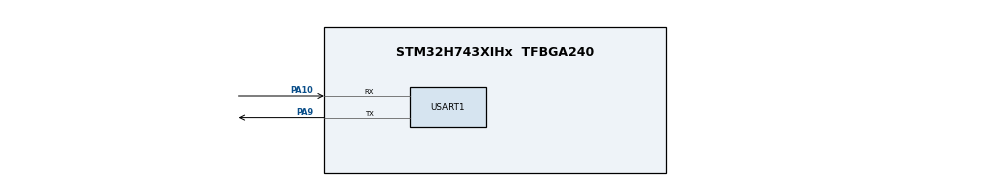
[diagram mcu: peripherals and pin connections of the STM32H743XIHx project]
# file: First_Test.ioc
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Dma.Request0=USART1_RX
Dma.Request1=USART1_TX
Dma.USART1_RX.0.Direction=DMA_PERIPH_TO_MEMORY
Dma.USART1_RX.0.EventEnable=DISABLE
Dma.USART1_RX.0.FIFOMode=DMA_FIFOMODE_DISABLE
Dma.USART1_RX.0.Instance=DMA1_Stream0
Dma.USART1_RX.0.MemDataAlignment=DMA_MDATAALIGN_BYTE
Dma.USART1_RX.0.MemInc=DMA_MINC_ENABLE
Dma.USART1_RX.0.Mode=DMA_NORMAL
Dma.USART1_RX.0.PeriphDataAlignment=DMA_PDATAALIGN_BYTE
Dma.USART1_RX.0.PeriphInc=DMA_PINC_DISABLE
Dma.USART1_RX.0.Polarity=HAL_DMAMUX_REQ_GEN_RISING
Dma.USART1_RX.0.Priority=DMA_PRIORITY_LOW
Dma.USART1_RX.0.RequestNumber=1
Dma.USART1_RX.0.SignalID=NONE
Dma.USART1_RX.0.SyncEnable=DISABLE
Dma.USART1_RX.0.SyncPolarity=HAL_DMAMUX_SYNC_NO_EVENT
Dma.USART1_RX.0.SyncRequestNumber=1
Dma.USART1_RX.0.SyncSignalID=NONE
Dma.USART1_TX.1.Direction=DMA_MEMORY_TO_PERIPH
Dma.USART1_TX.1.EventEnable=DISABLE
Dma.USART1_TX.1.FIFOMode=DMA_FIFOMODE_DISABLE
Dma.USART1_TX.1.Instance=DMA1_Stream1
Dma.USART1_TX.1.MemDataAlignment=DMA_MDATAALIGN_BYTE
Dma.USART1_TX.1.MemInc=DMA_MINC_ENABLE
Dma.USART1_TX.1.Mode=DMA_NORMAL
Dma.USART1_TX.1.PeriphDataAlignment=DMA_PDATAALIGN_BYTE
Dma.USART1_TX.1.PeriphInc=DMA_PINC_DISABLE
Dma.USART1_TX.1.Polarity=HAL_DMAMUX_REQ_GEN_RISING
Dma.USART1_TX.1.Priority=DMA_PRIORITY_LOW
Dma.USART1_TX.1.RequestNumber=1
Dma.USART1_TX.1.SignalID=NONE
Dma.USART1_TX.1.SyncEnable=DISABLE
Dma.USART1_TX.1.SyncPolarity=HAL_DMAMUX_SYNC_NO_EVENT
Dma.USART1_TX.1.SyncRequestNumber=1
Dma.USART1_TX.1.SyncSignalID=NONE
Mcu.Family=STM32H7
Mcu.Name=STM32H743XIHx
Mcu.Package=TFBGA240
NVIC.DMA1_Stream0_IRQn=true\:0\:0\:false\:false\:true\:false\:true\:true
NVIC.DMA1_Stream1_IRQn=true\:0\:0\:false\:false\:true\:false\:true\:true
NVIC.PriorityGroup=NVIC_PRIORITYGROUP_4
NVIC.USART1_IRQn=true\:1\:0\:true\:false\:true\:true\:true\:true
PA10.Mode=Asynchronous
PA10.Signal=USART1_RX
PA9.Mode=Asynchronous
PA9.Signal=USART1_TX
PH0-OSC_IN\ (PH0).Mode=HSE-External-Oscillator
PH0-OSC_IN\ (PH0).Signal=RCC_OSC_IN
PH1-OSC_OUT\ (PH1).Mode=HSE-External-Oscillator
PH1-OSC_OUT\ (PH1).Signal=RCC_OSC_OUT
ProjectManager.HeapSize=0x200
ProjectManager.StackSize=0x400
ProjectManager.TargetToolchain=MDK-ARM V5.32
RCC.ADCFreq_Value=50390625
RCC.APB1Freq_Value=100000000
RCC.APB2Freq_Value=100000000
RCC.APB3Freq_Value=100000000
RCC.APB4Freq_Value=100000000
RCC.CortexFreq_Value=400000000
RCC.D1PPRE=RCC_APB3_DIV2
RCC.D2PPRE1=RCC_APB1_DIV2
RCC.D2PPRE2=RCC_APB2_DIV2
RCC.D3PPRE=RCC_APB4_DIV2
RCC.DIVM1=5
RCC.DIVN1=160
RCC.HCLKFreq_Value=200000000
RCC.HPRE=RCC_HCLK_DIV2
RCC.PLL2FRACN=0
RCC.PLL3FRACN=0
RCC.PLLFRACN=0
RCC.PLLSourceVirtual=RCC_PLLSOURCE_HSE
RCC.SYSCLKFreq_VALUE=400000000
RCC.SYSCLKSource=RCC_SYSCLKSOURCE_PLLCLK
RCC.USBFreq_Value=400000000
USART1.VirtualMode-Asynchronous=VM_ASYNC
board=custom

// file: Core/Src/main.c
/* USER CODE BEGIN Header */
/**
  ******************************************************************************
  * @file           : main.c
  * @brief          : Main program body
  ******************************************************************************
  * @attention
  *
  * Copyright (c) 2023 STMicroelectronics.
  * All rights reserved.
  *
  * This software is licensed under terms that can be found in the LICENSE file
  * in the root directory of this software component.
  * If no LICENSE file comes with this software, it is provided AS-IS.
  * 串口收发-DMA+串口空闲中断
  ******************************************************************************
  */
/* USER CODE END Header */
#include "main.h"
#include "dma.h"
#include "usart.h"
#include "gpio.h"

/* USER CODE BEGIN PV */
uint8_t date[BUFLEN];
/* USER CODE END PV */

void SystemClock_Config(void);

/* USER CODE BEGIN 0 */

void HAL_UART_RxCpltCallback(UART_HandleTypeDef *huart)  //接收中断回调函数
{
    HAL_UART_Transmit_DMA(&huart1,date,BUFLEN);
    HAL_UART_Receive_IT(&huart1,date,BUFLEN);
}
/* USER CODE END 0 */

int main(void)
{

  /* MCU Configuration--------------------------------------------------------*/

  /* Reset of all peripherals, Initializes the Flash interface and the Systick. */
  HAL_Init();

  /* Configure the system clock */
  SystemClock_Config();

  /* Initialize all configured peripherals */
  MX_GPIO_Init();
  MX_DMA_Init();
  MX_USART1_UART_Init();
  /* USER CODE BEGIN 2 */
    HAL_UART_Receive_DMA(&huart1,date,20);
    __HAL_UART_CLEAR_IDLEFLAG(&huart1);  				//清空中断标志
    __HAL_UART_ENABLE_IT(&huart1, UART_IT_IDLE);// 使能串口空闲中断
    uint8_t data[] = "串口空闲中断";
    HAL_UART_Transmit(&huart1,data,sizeof("串口空闲中断")-1,50);
  /* USER CODE END 2 */

  /* Infinite loop */
  while (1)
  {

  }
}

void SystemClock_Config(void)
{
  RCC_OscInitTypeDef RCC_OscInitStruct = {0};
  RCC_ClkInitTypeDef RCC_ClkInitStruct = {0};

  /** Supply configuration update enable
  */
  HAL_PWREx_ConfigSupply(PWR_LDO_SUPPLY);

  /** Configure the main internal regulator output voltage
  */
  __HAL_PWR_VOLTAGESCALING_CONFIG(PWR_REGULATOR_VOLTAGE_SCALE1);

  while(!__HAL_PWR_GET_FLAG(PWR_FLAG_VOSRDY)) {}

  /** Initializes the RCC Oscillators according to the specified parameters
  * in the RCC_OscInitTypeDef structure.
  */
  RCC_OscInitStruct.OscillatorType = RCC_OSCILLATORTYPE_HSE;
  RCC_OscInitStruct.HSEState = RCC_HSE_ON;
  RCC_OscInitStruct.PLL.PLLState = RCC_PLL_ON;
  RCC_OscInitStruct.PLL.PLLSource = RCC_PLLSOURCE_HSE;
  RCC_OscInitStruct.PLL.PLLM = 5;
  RCC_OscInitStruct.PLL.PLLN = 160;
  RCC_OscInitStruct.PLL.PLLP = 2;
  RCC_OscInitStruct.PLL.PLLQ = 2;
  RCC_OscInitStruct.PLL.PLLR = 2;
  RCC_OscInitStruct.PLL.PLLRGE = RCC_PLL1VCIRANGE_2;
  RCC_OscInitStruct.PLL.PLLVCOSEL = RCC_PLL1VCOWIDE;
  RCC_OscInitStruct.PLL.PLLFRACN = 0;
  if (HAL_RCC_OscConfig(&RCC_OscInitStruct) != HAL_OK)
  {
    Error_Handler();
  }

  /** Initializes the CPU, AHB and APB buses clocks
  */
  RCC_ClkInitStruct.ClockType = RCC_CLOCKTYPE_HCLK|RCC_CLOCKTYPE_SYSCLK
                              |RCC_CLOCKTYPE_PCLK1|RCC_CLOCKTYPE_PCLK2
                              |RCC_CLOCKTYPE_D3PCLK1|RCC_CLOCKTYPE_D1PCLK1;
  RCC_ClkInitStruct.SYSCLKSource = RCC_SYSCLKSOURCE_PLLCLK;
  RCC_ClkInitStruct.SYSCLKDivider = RCC_SYSCLK_DIV1;
  RCC_ClkInitStruct.AHBCLKDivider = RCC_HCLK_DIV2;
  RCC_ClkInitStruct.APB3CLKDivider = RCC_APB3_DIV2;
  RCC_ClkInitStruct.APB1CLKDivider = RCC_APB1_DIV2;
  RCC_ClkInitStruct.APB2CLKDivider = RCC_APB2_DIV2;
  RCC_ClkInitStruct.APB4CLKDivider = RCC_APB4_DIV2;

  if (HAL_RCC_ClockConfig(&RCC_ClkInitStruct, FLASH_LATENCY_2) != HAL_OK)
  {
    Error_Handler();
  }
}

void Error_Handler(void)
{
  __disable_irq();
  while (1)
  {
  }
}
